# BL808 register map
Vendor: Bouffalo Lab; File version: 0.1
Registers are 32-bit, read-write, reset 0x0 unless marked. A register's access mark holds for its fields unless they carry their own. Offsets are from the block's base; [hi:lo] are bit positions; {n}, {i} and the like mark numbered series.

## AON — Always-On function control
Base 0x2000F800
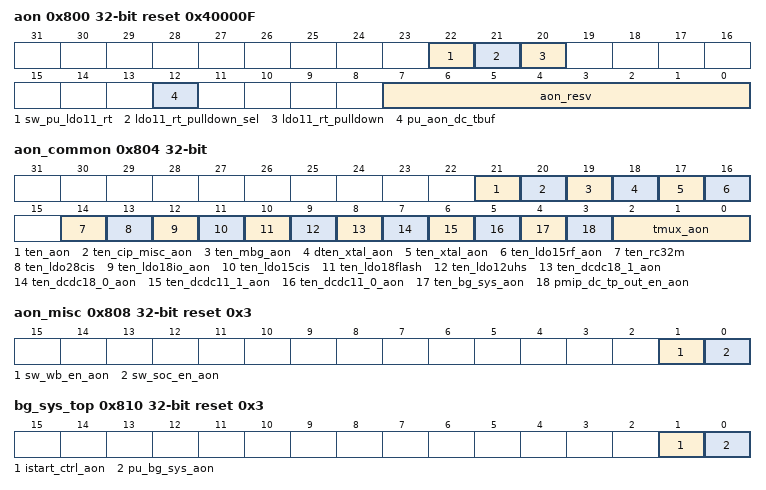
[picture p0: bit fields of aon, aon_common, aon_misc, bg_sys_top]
0x800 aon reset 0x40000F
  [22] sw_pu_ldo11_rt, [21] ldo11_rt_pulldown_sel, [20] ldo11_rt_pulldown, [12] pu_aon_dc_tbuf, [7:0] aon_resv
0x804 aon_common
  [21] ten_aon, [20] ten_cip_misc_aon, [19] ten_mbg_aon, [18] dten_xtal_aon, [17] ten_xtal_aon, [16] ten_ldo15rf_aon, [14] ten_rc32m, [13] ten_ldo28cis, [12] ten_ldo18io_aon, [11] ten_ldo15cis, [10] ten_ldo18flash, [9] ten_ldo12uhs, [8] ten_dcdc18_1_aon, [7] ten_dcdc18_0_aon, [6] ten_dcdc11_1_aon, [5] ten_dcdc11_0_aon, [4] ten_bg_sys_aon, [3] pmip_dc_tp_out_en_aon, [2:0] tmux_aon
0x808 aon_misc reset 0x3
  [1] sw_wb_en_aon, [0] sw_soc_en_aon
0x810 bg_sys_top reset 0x3
  [1] istart_ctrl_aon, [0] pu_bg_sys_aon
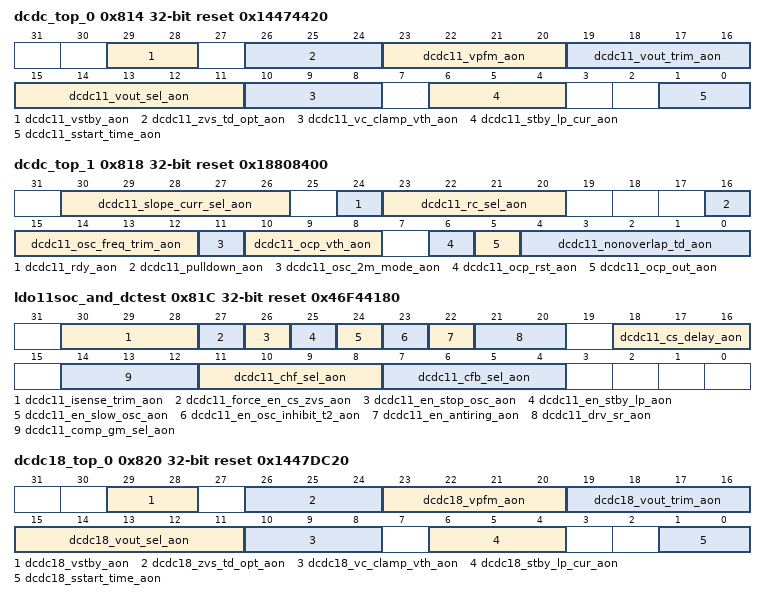
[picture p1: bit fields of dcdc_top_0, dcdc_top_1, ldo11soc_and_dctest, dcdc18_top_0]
0x814 dcdc_top_0 reset 0x14474420
  [29:28] dcdc11_vstby_aon, [26:24] dcdc11_zvs_td_opt_aon, [23:20] dcdc11_vpfm_aon, [19:16] dcdc11_vout_trim_aon, [15:11] dcdc11_vout_sel_aon, [10:8] dcdc11_vc_clamp_vth_aon, [6:4] dcdc11_stby_lp_cur_aon, [1:0] dcdc11_sstart_time_aon
0x818 dcdc_top_1 reset 0x18808400
  [30:26] dcdc11_slope_curr_sel_aon, [24] dcdc11_rdy_aon ro, [23:20] dcdc11_rc_sel_aon, [16] dcdc11_pulldown_aon, [15:12] dcdc11_osc_freq_trim_aon, [11] dcdc11_osc_2m_mode_aon, [10:8] dcdc11_ocp_vth_aon, [6] dcdc11_ocp_rst_aon, [5] dcdc11_ocp_out_aon ro, [4:0] dcdc11_nonoverlap_td_aon
0x81C ldo11soc_and_dctest reset 0x46F44180
  [30:28] dcdc11_isense_trim_aon, [27] dcdc11_force_en_cs_zvs_aon, [26] dcdc11_en_stop_osc_aon, [25] dcdc11_en_stby_lp_aon, [24] dcdc11_en_slow_osc_aon, [23] dcdc11_en_osc_inhibit_t2_aon, [22] dcdc11_en_antiring_aon, [21:20] dcdc11_drv_sr_aon, [18:16] dcdc11_cs_delay_aon, [14:12] dcdc11_comp_gm_sel_aon, [11:8] dcdc11_chf_sel_aon, [7:4] dcdc11_cfb_sel_aon
0x820 dcdc18_top_0 reset 0x1447DC20 — move to 0x2000F000[23]
  [29:28] dcdc18_vstby_aon, [26:24] dcdc18_zvs_td_opt_aon, [23:20] dcdc18_vpfm_aon, [19:16] dcdc18_vout_trim_aon, [15:11] dcdc18_vout_sel_aon, [10:8] dcdc18_vc_clamp_vth_aon, [6:4] dcdc18_stby_lp_cur_aon, [1:0] dcdc18_sstart_time_aon
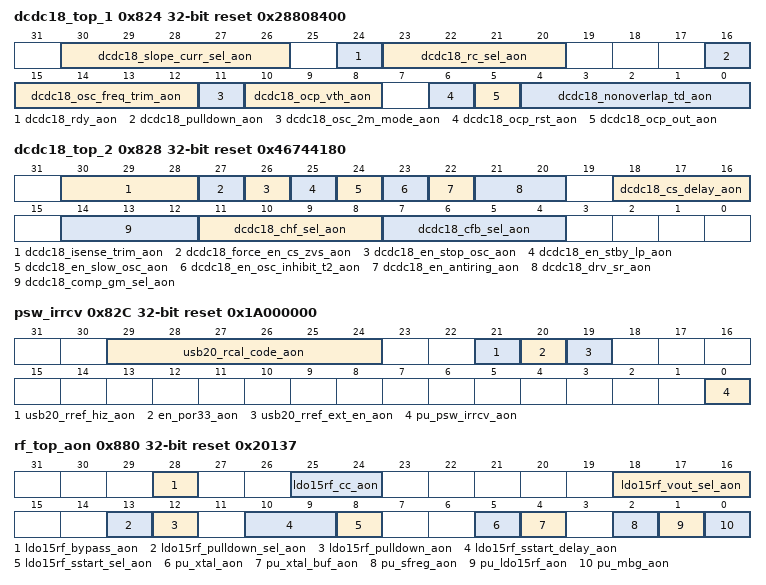
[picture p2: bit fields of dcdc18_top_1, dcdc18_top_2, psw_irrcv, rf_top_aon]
0x824 dcdc18_top_1 reset 0x28808400
  [30:26] dcdc18_slope_curr_sel_aon, [24] dcdc18_rdy_aon ro, [23:20] dcdc18_rc_sel_aon, [16] dcdc18_pulldown_aon, [15:12] dcdc18_osc_freq_trim_aon, [11] dcdc18_osc_2m_mode_aon, [10:8] dcdc18_ocp_vth_aon, [6] dcdc18_ocp_rst_aon, [5] dcdc18_ocp_out_aon ro, [4:0] dcdc18_nonoverlap_td_aon
0x828 dcdc18_top_2 reset 0x46744180
  [30:28] dcdc18_isense_trim_aon, [27] dcdc18_force_en_cs_zvs_aon, [26] dcdc18_en_stop_osc_aon, [25] dcdc18_en_stby_lp_aon, [24] dcdc18_en_slow_osc_aon, [23] dcdc18_en_osc_inhibit_t2_aon, [22] dcdc18_en_antiring_aon, [21:20] dcdc18_drv_sr_aon, [18:16] dcdc18_cs_delay_aon, [14:12] dcdc18_comp_gm_sel_aon, [11:8] dcdc18_chf_sel_aon, [7:4] dcdc18_cfb_sel_aon
0x82C psw_irrcv reset 0x1A000000
  [29:24] usb20_rcal_code_aon, [21] usb20_rref_hiz_aon, [20] en_por33_aon, [19] usb20_rref_ext_en_aon, [0] pu_psw_irrcv_aon
0x880 rf_top_aon reset 0x20137
  [28] ldo15rf_bypass_aon, [25:24] ldo15rf_cc_aon, [18:16] ldo15rf_vout_sel_aon, [13] ldo15rf_pulldown_sel_aon, [12] ldo15rf_pulldown_aon, [10:9] ldo15rf_sstart_delay_aon, [8] ldo15rf_sstart_sel_aon, [5] pu_xtal_aon, [4] pu_xtal_buf_aon, [2] pu_sfreg_aon, [1] pu_ldo15rf_aon, [0] pu_mbg_aon
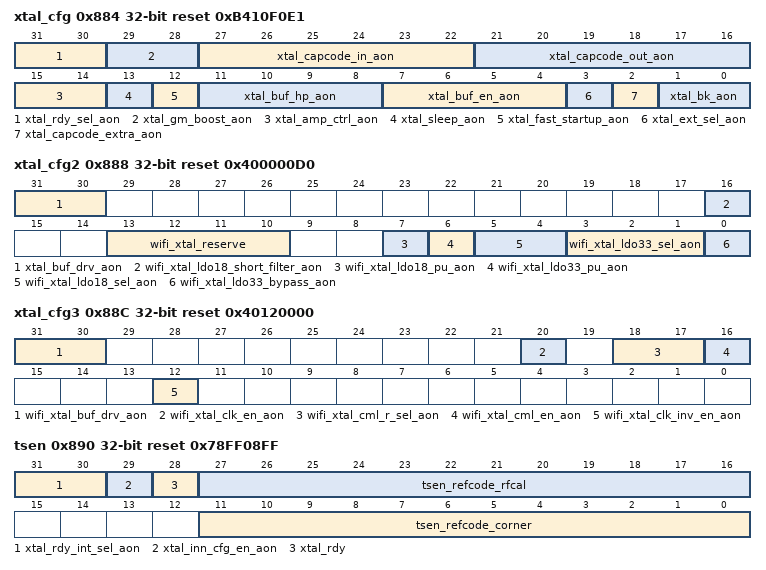
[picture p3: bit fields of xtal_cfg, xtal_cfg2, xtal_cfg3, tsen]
0x884 xtal_cfg reset 0xB410F0E1
  [31:30] xtal_rdy_sel_aon, [29:28] xtal_gm_boost_aon, [27:22] xtal_capcode_in_aon, [21:16] xtal_capcode_out_aon, [15:14] xtal_amp_ctrl_aon, [13] xtal_sleep_aon, [12] xtal_fast_startup_aon, [11:8] xtal_buf_hp_aon, [7:4] xtal_buf_en_aon, [3] xtal_ext_sel_aon, [2] xtal_capcode_extra_aon, [1:0] xtal_bk_aon
0x888 xtal_cfg2 reset 0x400000D0
  [31:30] xtal_buf_drv_aon, [16] wifi_xtal_ldo18_short_filter_aon, [13:10] wifi_xtal_reserve, [7] wifi_xtal_ldo18_pu_aon, [6] wifi_xtal_ldo33_pu_aon, [5:4] wifi_xtal_ldo18_sel_aon, [3:1] wifi_xtal_ldo33_sel_aon, [0] wifi_xtal_ldo33_bypass_aon
0x88C xtal_cfg3 reset 0x40120000
  [31:30] wifi_xtal_buf_drv_aon, [20] wifi_xtal_clk_en_aon, [18:17] wifi_xtal_cml_r_sel_aon, [16] wifi_xtal_cml_en_aon, [12] wifi_xtal_clk_inv_en_aon
0x890 tsen reset 0x78FF08FF
  [31:30] xtal_rdy_int_sel_aon, [29] xtal_inn_cfg_en_aon, [28] xtal_rdy ro, [27:16] tsen_refcode_rfcal, [11:0] tsen_refcode_corner
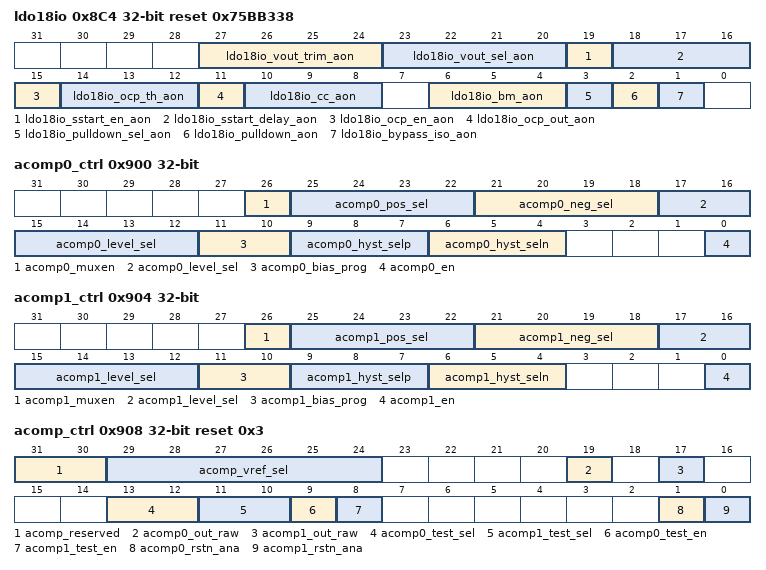
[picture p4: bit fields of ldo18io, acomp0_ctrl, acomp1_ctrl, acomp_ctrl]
0x8C4 ldo18io reset 0x75BB338
  [27:24] ldo18io_vout_trim_aon, [23:20] ldo18io_vout_sel_aon, [19] ldo18io_sstart_en_aon, [18:16] ldo18io_sstart_delay_aon, [15] ldo18io_ocp_en_aon, [14:12] ldo18io_ocp_th_aon, [11] ldo18io_ocp_out_aon ro, [10:8] ldo18io_cc_aon, [6:4] ldo18io_bm_aon, [3] ldo18io_pulldown_sel_aon, [2] ldo18io_pulldown_aon, [1] ldo18io_bypass_iso_aon
0x900 acomp0_ctrl
  [26] acomp0_muxen, [25:22] acomp0_pos_sel, [21:18] acomp0_neg_sel, [17:12] acomp0_level_sel, [11:10] acomp0_bias_prog, [9:7] acomp0_hyst_selp, [6:4] acomp0_hyst_seln, [0] acomp0_en
0x904 acomp1_ctrl
  [26] acomp1_muxen, [25:22] acomp1_pos_sel, [21:18] acomp1_neg_sel, [17:12] acomp1_level_sel, [11:10] acomp1_bias_prog, [9:7] acomp1_hyst_selp, [6:4] acomp1_hyst_seln, [0] acomp1_en
0x908 acomp_ctrl reset 0x3
  [31:30] acomp_reserved, [29:24] acomp_vref_sel, [19] acomp0_out_raw ro, [17] acomp1_out_raw ro, [13:12] acomp0_test_sel, [11:10] acomp1_test_sel, [9] acomp0_test_en, [8] acomp1_test_en, [1] acomp0_rstn_ana, [0] acomp1_rstn_ana
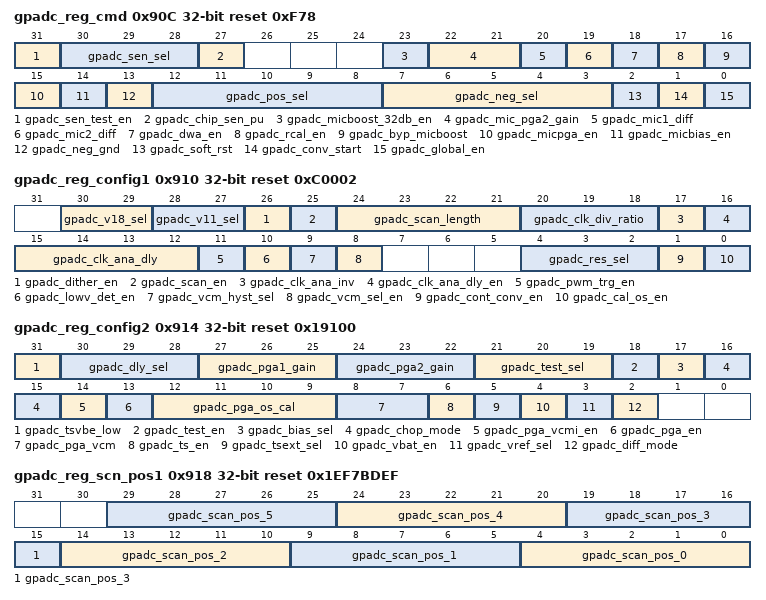
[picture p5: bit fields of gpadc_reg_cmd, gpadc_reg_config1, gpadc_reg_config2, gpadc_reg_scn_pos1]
0x90C gpadc_reg_cmd reset 0xF78
  [31] gpadc_sen_test_en, [30:28] gpadc_sen_sel, [27] gpadc_chip_sen_pu, [23] gpadc_micboost_32db_en, [22:21] gpadc_mic_pga2_gain, [20] gpadc_mic1_diff, [19] gpadc_mic2_diff, [18] gpadc_dwa_en, [17] gpadc_rcal_en, [16] gpadc_byp_micboost, [15] gpadc_micpga_en, [14] gpadc_micbias_en, [13] gpadc_neg_gnd, [12:8] gpadc_pos_sel, [7:3] gpadc_neg_sel, [2] gpadc_soft_rst, [1] gpadc_conv_start, [0] gpadc_global_en
0x910 gpadc_reg_config1 reset 0xC0002
  [30:29] gpadc_v18_sel, [28:27] gpadc_v11_sel, [26] gpadc_dither_en, [25] gpadc_scan_en, [24:21] gpadc_scan_length, [20:18] gpadc_clk_div_ratio, [17] gpadc_clk_ana_inv, [16] gpadc_clk_ana_dly_en, [15:12] gpadc_clk_ana_dly, [11] gpadc_pwm_trg_en, [10] gpadc_lowv_det_en, [9] gpadc_vcm_hyst_sel, [8] gpadc_vcm_sel_en, [4:2] gpadc_res_sel, [1] gpadc_cont_conv_en, [0] gpadc_cal_os_en
0x914 gpadc_reg_config2 reset 0x19100
  [31] gpadc_tsvbe_low, [30:28] gpadc_dly_sel, [27:25] gpadc_pga1_gain, [24:22] gpadc_pga2_gain, [21:19] gpadc_test_sel, [18] gpadc_test_en, [17] gpadc_bias_sel, [16:15] gpadc_chop_mode, [14] gpadc_pga_vcmi_en, [13] gpadc_pga_en, [12:9] gpadc_pga_os_cal, [8:7] gpadc_pga_vcm, [6] gpadc_ts_en, [5] gpadc_tsext_sel, [4] gpadc_vbat_en, [3] gpadc_vref_sel, [2] gpadc_diff_mode
0x918 gpadc_reg_scn_pos1 reset 0x1EF7BDEF — adc converation sequence 1
  [5n+4:5n] gpadc_scan_pos_{n} (n=0..5)
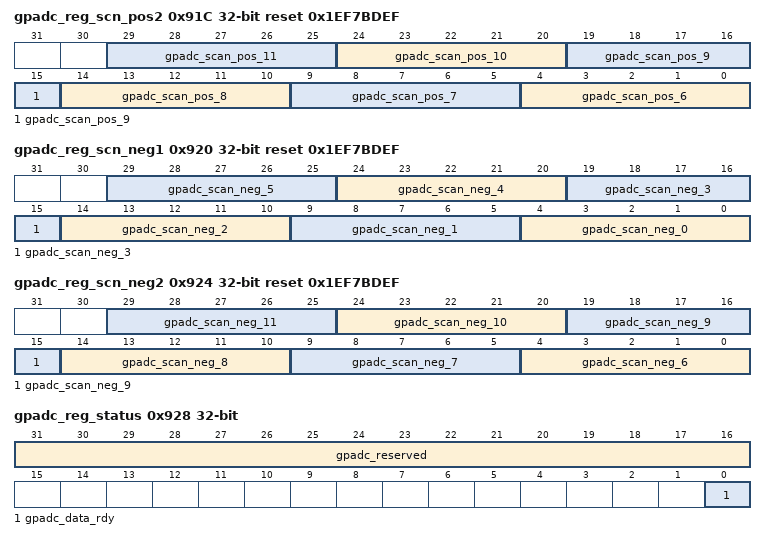
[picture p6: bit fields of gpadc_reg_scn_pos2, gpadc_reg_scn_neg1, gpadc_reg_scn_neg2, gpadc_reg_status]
0x91C gpadc_reg_scn_pos2 reset 0x1EF7BDEF — adc converation sequence 2
  [5n-26:5n-30] gpadc_scan_pos_{n} (n=6..11)
0x920 gpadc_reg_scn_neg1 reset 0x1EF7BDEF — adc converation sequence 3
  [5n+4:5n] gpadc_scan_neg_{n} (n=0..5)
0x924 gpadc_reg_scn_neg2 reset 0x1EF7BDEF — adc converation sequence 4
  [5n-26:5n-30] gpadc_scan_neg_{n} (n=6..11)
0x928 gpadc_reg_status
  [31:16] gpadc_reserved, [0] gpadc_data_rdy ro
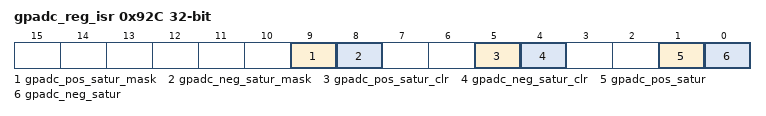
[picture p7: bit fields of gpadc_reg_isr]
0x92C gpadc_reg_isr
  [9] gpadc_pos_satur_mask, [8] gpadc_neg_satur_mask, [5] gpadc_pos_satur_clr, [4] gpadc_neg_satur_clr, [1] gpadc_pos_satur ro, [0] gpadc_neg_satur ro
0x930 gpadc_reg_result reset 0x1EF0000
  [25:0] gpadc_data_out ro
0x934 gpadc_reg_raw_result
  [11:0] gpadc_raw_data ro
0x938 gpadc_reg_define
  [15:0] gpadc_os_cal_data
0x93C hbncore_resv0
  [31:0] hbncore_resv0_data
0x940 hbncore_resv1 reset 0xFFFFFFFF
  [31:0] hbncore_resv1_data
